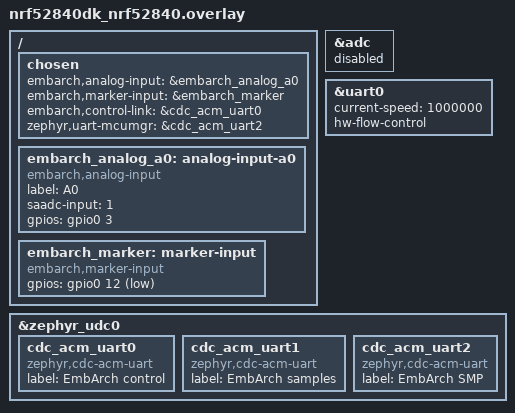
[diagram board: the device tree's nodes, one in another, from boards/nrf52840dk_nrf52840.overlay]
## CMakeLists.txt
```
# Shared application build (embarch-dev-bench/design.md §2) -- referenced,
# not copied, by every workspace under workspaces/*/app.

cmake_minimum_required(VERSION 3.20.0)

find_package(Zephyr REQUIRED HINTS $ENV{ZEPHYR_BASE})
project(embarch_dev_bench)

target_include_directories(app PRIVATE src)

target_sources(app PRIVATE
  src/main.c
  src/serial_protocol.c
  # EmbArch USB identity arithmetic (VID, PID, serial string); pure, so it
  # builds everywhere and a native_sim test pins it.
  src/usb_ids.c
  # embarch-study-designer/design.md §3 decisions 58-62: the `.eap` protocol
  # interpreter. Built for every board, including native_sim -- it is pure C
  # with no BLE and no Zephyr in it, which is what lets the ztest suite drive
  # the semantics directly (there is no real-vs-stub split to make here).
  src/eap_interp.c
  # embarch-dev-bench/design.md §3 decision 38: the Zephyr log backend that
  # forwards CONFIG_LOG output to Core as `LogLine`s. Built for every board,
  # including native_sim -- unlike ble_bridge there is no real-vs-stub
  # split here, since the file itself compiles to no-ops under CONFIG_LOG=n.
  src/dev_bench_log.c
  # decision 44: the advertiser census's Manufacturer Specific Data parsing and
  # rendering. Built for every board including native_sim, same reasoning as
  # eap_interp.c above -- it needs Zephyr's printk/util helpers but nothing
  # from the BT host, so a ztest can pin its offset arithmetic against a
  # synthetic payload on a board where ble_bridge_real.c itself never builds.
  src/scan_seen_mfg.c
  # dev-bench/007: the same failed-name census's bounded, no-partial-fragment
  # name-list append -- built for every board including native_sim, same
  # reasoning as scan_seen_mfg.c above, so a ztest can pin its truncation
  # behaviour even though ble_bridge_real.c itself never builds here.
  src/scan_seen_names.c
)

# The analog capture (dev-bench decisions 60 and 64): framing and sessions are
# pure and build everywhere, so a native_sim test drives them with a fake
# backend; only the backend and the USB port depend on the SoC.
target_sources(app PRIVATE
  src/analog_stream.c
  # Core's StudyStop, read while a study runs; pure, so a native_sim test drives it.
  src/study_stop.c
  src/analog_capture.c
)
if(CONFIG_SOC_SERIES_NRF52)
  # The one stated exception to portable-APIs-only (decision 60): nrfx SAADC.
  target_sources(app PRIVATE src/analog_source_nrf52.c)
else()
  target_sources(app PRIVATE src/analog_source_none.c)
endif()
target_sources_ifdef(CONFIG_USB_DEVICE_STACK_NEXT app PRIVATE src/samples_port.c)

# The native USB composite device, only where a board conf selects the "next"
# USB device stack (the nRF52840 DK).
target_sources_ifdef(CONFIG_USB_DEVICE_STACK_NEXT app PRIVATE src/usb_device.c)

# UICR REGOUT0 = 3.3 V at boot (nRF52840 DK on native USB), see the file.
target_sources_ifdef(CONFIG_EMBARCH_DEV_BENCH_REGOUT0_3V3 app PRIVATE src/board_regout0.c)

# embarch-dev-bench/design.md §3 decision 16: ble_bridge_real.c (real Zephyr BT
# host calls) vs ble_bridge_stub.c (canned Outcomes, no BLE host) are separate
# files, not #ifdef branches inside one -- CONFIG_ARCH_POSIX is true exactly
# for native_sim among this project's targets, so it's what picks between them.
if(CONFIG_ARCH_POSIX)
  target_sources(app PRIVATE src/ble_bridge_stub.c)
else()
  target_sources(app PRIVATE src/ble_bridge_real.c)
endif()

# embarch-dev-bench/design.md §3 decision 18: HelloAck.firmware_version.
# Best-effort `git describe`; falls back to a fixed placeholder outside a git
# checkout (e.g. a source tarball) or without git installed.
#
# Real bug found and fixed validating embarch-umbrella's stale-firmware
# doctor check (decision 25) against two real commits: `execute_process`
# only runs at CMake *configure* time, and CMake only reconfigures when one
# of its own tracked dependencies changes -- by default just CMakeLists.txt
# itself, not "the git commit checked out right now." An incremental
# `west build` after a plain `git commit` (no CMakeLists.txt edit) was
# silently re-linking with the *previous* configure's now-stale
# APP_FIRMWARE_VERSION baked in, for every translation unit, not just ones
# that happened to recompile -- exactly the false-negative decision 25's
# check exists to catch, self-inflicted by the build system itself. Fixed by
# making the checked-out commit itself a tracked configure dependency, so a
# commit (or branch switch) that changes it forces a reconfigure and a fresh
# `git describe`. Doesn't cover the plain-`--dirty` case (editing a tracked
# file without staging or committing touches neither of these) -- inherent
# to any git-describe-based scheme, not something CONFIGURE_DEPENDS can fix.
execute_process(
  COMMAND git rev-parse --git-dir
  WORKING_DIRECTORY ${CMAKE_CURRENT_SOURCE_DIR}
  OUTPUT_VARIABLE _embarch_git_dir
  OUTPUT_STRIP_TRAILING_WHITESPACE
  ERROR_QUIET
)
if(_embarch_git_dir)
  if(NOT IS_ABSOLUTE "${_embarch_git_dir}")
    set(_embarch_git_dir "${CMAKE_CURRENT_SOURCE_DIR}/${_embarch_git_dir}")
  endif()
  if(EXISTS "${_embarch_git_dir}/HEAD")
    set_property(DIRECTORY APPEND PROPERTY CMAKE_CONFIGURE_DEPENDS "${_embarch_git_dir}/HEAD")
    file(READ "${_embarch_git_dir}/HEAD" _embarch_head_contents)
    if(_embarch_head_contents MATCHES "^ref: (.*)$")
      string(STRIP "${CMAKE_MATCH_1}" _embarch_head_ref)
      set_property(DIRECTORY APPEND PROPERTY CMAKE_CONFIGURE_DEPENDS "${_embarch_git_dir}/${_embarch_head_ref}")
    endif()
  endif()
  if(EXISTS "${_embarch_git_dir}/index")
    set_property(DIRECTORY APPEND PROPERTY CMAKE_CONFIGURE_DEPENDS "${_embarch_git_dir}/index")
  endif()
endif()

execute_process(
  COMMAND git describe --always --dirty --abbrev=8
  WORKING_DIRECTORY ${CMAKE_CURRENT_SOURCE_DIR}
  OUTPUT_VARIABLE APP_FIRMWARE_VERSION
  OUTPUT_STRIP_TRAILING_WHITESPACE
  ERROR_QUIET
)
if(NOT APP_FIRMWARE_VERSION)
  set(APP_FIRMWARE_VERSION "unknown")
endif()
target_compile_definitions(app PRIVATE APP_FIRMWARE_VERSION="${APP_FIRMWARE_VERSION}")

# Where embarch-study-designer lives. No target links the crate; every target
# reads its wire schema version and its limits and wire enums out of the
# crate's source at configure time, because hand-mirroring them is how the
# schema number went stale twice (see below).
if(DEFINED ENV{EMBARCH_STUDY_DESIGNER_PATH})
  set(ESSD_DIR "$ENV{EMBARCH_STUDY_DESIGNER_PATH}")
else()
  # CMAKE_CURRENT_SOURCE_DIR here is workspaces/<name>/app, itself a
  # symlink to the real app/ (§2's tree). Resolve *that* symlink first, in
  # its own get_filename_component call -- CMake's REALPATH collapses ".."
  # textually before resolving symlinks, so appending "../../embarch-study-
  # designer" and resolving in one call never actually follows the
  # symlink: the ".." components cancel the still-unresolved "app" segment
  # lexically, landing in workspaces/embarch-study-designer (which doesn't
  # exist) instead of climbing out of the real app/'s real parent. Found
  # standing up workspaces/espressif (embarch-dev-bench/design.md's
  # ESP32-C5 interim decision) -- a real CMake-path-resolution bug, latent
  # in every other workspace too, just unnoticed because plain ABSOLUTE
  # (the original code here) happened to still be wrong in the same way
  # nobody hit until a workspace where the surrounding symlink chain
  # differed enough to surface it.
  get_filename_component(ESSD_APP_REALDIR "${CMAKE_CURRENT_SOURCE_DIR}" REALPATH)
  get_filename_component(ESSD_DIR "${ESSD_APP_REALDIR}/../../embarch-study-designer" ABSOLUTE)
endif()
if(NOT EXISTS "${ESSD_DIR}/Cargo.toml")
  message(FATAL_ERROR "embarch-dev-bench: embarch-study-designer not found at ${ESSD_DIR} -- set EMBARCH_STUDY_DESIGNER_PATH if it isn't a sibling of this repo.")
endif()

# Every crate limit and `.eap` wire enum the headers size or decode by,
# derived from the crate rather than typed (decision 56).
include(${CMAKE_CURRENT_SOURCE_DIR}/cmake/crate_limits.cmake)

# The wire schema version `HelloAck` reports (decision 20), read out of the
# crate rather than mirrored by hand in C, for every target.
#
# It was a hand-written `#define`, and it went stale twice: found four bumps
# behind at v4 while implementing v9, fixed to 9, and found stale again at 9
# one bump later when decision 47 took the wire to 10. The comment written the
# first time already said nothing compares this number against the crate --
# which was true, and stayed true, and let the same defect recur immediately.
# Reading it from the crate's own source is what actually closes that, and the
# CONFIGURE_DEPENDS below is what makes an edit to that file re-run this
# instead of leaving a stale value baked in -- the same trap APP_FIRMWARE_VERSION
# hit above. Real boards used to get the number by cross-compiling the crate
# into a staticlib and calling into it (decision 8); that was the only live call
# into the staticlib, so the staticlib is gone and every board reads it here.
set(ESSD_SCHEMA_SRC "${ESSD_DIR}/src/schema_version.rs")
if(NOT EXISTS "${ESSD_SCHEMA_SRC}")
  message(FATAL_ERROR "embarch-dev-bench: ${ESSD_SCHEMA_SRC} not found -- the build reads DEV_BENCH_WIRE_SCHEMA_VERSION from it.")
endif()
set_property(DIRECTORY APPEND PROPERTY CMAKE_CONFIGURE_DEPENDS "${ESSD_SCHEMA_SRC}")
file(READ "${ESSD_SCHEMA_SRC}" _essd_schema_src)
if(NOT _essd_schema_src MATCHES "pub const DEV_BENCH_WIRE_SCHEMA_VERSION: u32 = ([0-9]+)")
  message(FATAL_ERROR "embarch-dev-bench: could not read DEV_BENCH_WIRE_SCHEMA_VERSION out of ${ESSD_SCHEMA_SRC}.")
endif()
target_compile_definitions(app PRIVATE DEV_BENCH_WIRE_SCHEMA_VERSION=${CMAKE_MATCH_1}u)
message(STATUS "embarch-dev-bench: dev-bench wire schema version ${CMAKE_MATCH_1} (from the crate)")
```

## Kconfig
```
# Application Kconfig, sourced automatically by Zephyr for the app directory.
# Shared by every workspace under workspaces/* (each one's app/ is a symlink to
# this directory, embarch-dev-bench/design.md §2).
#
# **An app Kconfig replaces Zephyr's own root, it does not extend it**, so it
# has to `source "Kconfig.zephyr"` itself or every Zephyr symbol vanishes and
# the build aborts on the resulting warnings. Found the hard way adding the
# first symbol here.

mainmenu "embarch-dev-bench"

config EMBARCH_DEV_BENCH_PANIC_AT_HANDSHAKE
	bool "Deliberately k_panic() right after the handshake diagnostic"
	help
	  A debug-only build that crashes on purpose, to exercise decision 38's
	  fatal-error path — the one part of it that has never run (§4).
	  log_panic() switching to synchronous, lock-free writing is what should
	  carry a Zephyr crash dump to Core as LogLines, and nothing has
	  deliberately crashed this firmware since it was written.

	  The question it answers is specific: dev-bench resets mid-study while
	  transmitting a long StepResult, and no crash dump ever arrives. That is
	  either because the reset is not a Zephyr panic, or because this path
	  does not deliver. A build that panics on command distinguishes them —
	  a dump in dev-bench.log means the path works and the real reset is
	  something else (brownout and a watchdog lead the alternatives); no dump
	  means the path itself is broken and the absence of one during a real
	  reset says nothing.

	  Never enable this in a build meant to run a study: it panics at every
	  handshake, so no study can start.
	default n

config EMBARCH_DEV_BENCH_REGOUT0_3V3
	bool "Set UICR REGOUT0 to 3.3 V at boot when unset"
	depends on SOC_NRF52840
	help
	  For an nRF52840 DK powered only from its native USB: the chip runs in
	  high-voltage mode and its VDD comes from regulator stage 0, whose
	  erased default is 1.8 V. With this on, board_regout0.c writes 3.3 V to
	  UICR REGOUT0 the first time it boots with the default, then resets
	  once, so an external analog front end gets 3.3 V on VDD.

config EMBARCH_ANALOG_MAX_CHANNELS
	int "Most analog channels one session can carry"
	range 1 8
	default 1
	help
	  Sizes every sample block buffer. The block format carries any channel
	  count; the only backend (nRF52 SAADC on its internal timer) samples
	  one channel, so a larger value only reserves RAM until a multi-channel
	  backend exists.

config EMBARCH_ANALOG_STREAM_SLOTS
	int "Sample blocks buffered between the ADC and the samples port"
	range 2 32
	default 8
	help
	  Each slot is one block (528 bytes for one channel, 8 ms at 32 ksps).
	  When all are in use the next block is dropped and counted, never
	  waited for.

config EMBARCH_SAMPLES_PORT_RING_BLOCKS
	int "Sample blocks the samples USB port can queue"
	depends on USB_DEVICE_STACK_NEXT
	range 2 32
	default 8
	help
	  The transmit ring in front of the samples CDC ACM port. A block that
	  does not fit whole is refused and counted lost.

source "Kconfig.zephyr"
```

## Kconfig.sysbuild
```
# Sysbuild Kconfig for this app. Replaces the sysbuild root, so it sources
# Zephyr's own first.
#
# MCUboot is built for the nRF52840 DK only (image updates over the SMP USB
# port). Every other board keeps its current flash layout: a default on the
# bootloader choice, set before Zephyr's own declaration so it is the first
# default found.
choice BOOTLOADER
	default BOOTLOADER_MCUBOOT if BOARD = "nrf52840dk"
endchoice

source "share/sysbuild/Kconfig"
```

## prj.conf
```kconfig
# Shared baseline Kconfig, both workspaces (embarch-dev-bench/design.md §2).

# embarch-dev-bench/design.md §3 decision 7: dev-bench's own log output
# travels as a `LogLine` DevBenchMessage, not raw text -- so nothing else
# (the boot banner, a log backend, the shell) may also write to the link UART
# (the board's `zephyr,console` chosen device, see main.c), or it would corrupt
# COBS framing on the shared wire. No on-board status indication for v1 either
# way (§1) -- this firmware's state is observable only through
# embarch-core/study_status, not local console output.
#
# CONFIG_CONSOLE itself is left alone (native_sim's board Kconfig
# unconditionally force-selects console support and errors out if this tries
# to turn it off) -- disabling the things that actually call printk/log on it
# is enough, since nothing else writes to this UART unprompted.
CONFIG_BOOT_BANNER=n

# --- logging subsystem (design.md §3 decision 38) ------------------------
#
# CONFIG_LOG was `n` here from decision 7 until decision 38, and that had a
# real cost: every LOG_* call in this app and in every Zephyr subsystem it uses
# (BT host, drivers) compiled to nothing, and so did the fatal-error dump, so a
# bench that rebooted or faulted mid-study was *completely silent* from Core's
# side (see main.c's handle_hello for the study that made that concrete). What
# decision 7 actually forbids is raw log text on the shared wire -- not the
# logging subsystem itself. dev_bench_log.c is a log backend that formats each
# record and hands it to a `LogLine`, i.e. exactly the channel decision 7
# specified, so the subsystem can be on without a byte of unframed text ever
# reaching the UART.
CONFIG_LOG=y
CONFIG_LOG_OUTPUT=y

# Deferred, never immediate, and this is load-bearing rather than a default
# worth restating: in immediate mode a backend runs in the caller's context,
# including ISRs and the BT RX thread, and dev_bench_log.c's sink takes
# main.c's `link_tx_mutex` and blocks on uart_poll_out -- illegal from an ISR
# and a latency spike everywhere else. Deferred mode moves every backend call
# onto the log processing thread, which is what makes one link writer more
# (alongside the dispatch loop and the transcript TX thread) safe.
CONFIG_LOG_MODE_DEFERRED=y
CONFIG_LOG_PROCESS_THREAD=y
# log_output formatting plus dbm_encode_frame's call depth on top of it. The
# 1 KB default is Zephyr's sizing for a UART backend that does neither.
CONFIG_LOG_PROCESS_THREAD_STACK_SIZE=2048

# The two backends Zephyr would otherwise enable *by default* on these boards,
# both of which would break something here:
#   - LOG_BACKEND_UART defaults to y whenever there is a UART console, and
#     that console IS this link -- it would write raw text straight onto the
#     COBS wire, the precise failure decision 7 exists to prevent. This line
#     is the single most important one in this block.
#   - LOG_BACKEND_RTT defaults to y on a SEGGER-probed board (the nRF54L15DK).
#     Harmless to the wire, but it costs RAM on boards whose SRAM has already
#     overflowed twice at link time (§3 decision 27, and main.c's tx_scratch
#     consolidation), for a second channel nothing in this suite reads.
CONFIG_LOG_BACKEND_UART=n
CONFIG_LOG_BACKEND_RTT=n

# A *protection*, not a convenience: with this on, any stray printk (Zephyr
# internals, a future line in this app) is routed through the logging
# subsystem and comes out as a framed `LogLine` instead of raw bytes on the
# protocol wire. Without it, one printk anywhere corrupts a frame -- which is
# why the ESP32-C5 overlay's own comment had to record "no stray printk on
# this path -- checked, not assumed" as a prerequisite for reading a decode
# failure. This makes that check unnecessary rather than merely passed.
CONFIG_LOG_PRINTK=y

# --- per-study verbosity (design.md §3 decision 39) ----------------------
#
# Decision 38 shipped CONFIG_LOG_DEFAULT_LEVEL=2, i.e. it kept the link quiet
# by *compiling out* everything above warn. That was the right instinct about
# bandwidth -- a 128-byte LogLine frame is ~1.3 ms of a 1 Mbaud wire the study
# protocol is also using -- and the wrong mechanism: it made the choice once,
# for every study, at whatever level whoever last edited this file picked. A
# BLE-heavy study that needed the BT host's own account of a failure could only
# get it by editing this line, rebuilding, and reflashing the bench.
#
# So: compile everything in, and filter at runtime per study instead. A
# `Study` carries `dev_bench_log_level` (embarch-study-designer's
# DevBenchLogLevel, schema v13), main.c applies it for the study's duration and
# reverts to DEV_BENCH_LOG_BOOT_LEVEL (warn) afterwards, so an idle bench is
# exactly as quiet as it was before this change.
#
# The cost of compiling in DBG is flash, not SRAM -- log format strings live in
# rodata, which on both supported boards is flash-mapped (the ESP32-C5's
# drom0_0_seg was at 0.55% of 8 MB). CONFIG_LOG_RUNTIME_FILTERING's own cost
# *is* SRAM (one filter word per log source), which is why the number below was
# measured against a real build rather than assumed.
CONFIG_LOG_DEFAULT_LEVEL=4
CONFIG_LOG_RUNTIME_FILTERING=y

# embarch-dev-bench/design.md §3 decision 21: `struct dev_bench_message`'s
# union now includes `struct dbm_study_start`, which embeds a full
# DBM_MAX_STEPS_PER_STUDY-sized `struct dbm_step` array (StudyStart's own
# wire worst case, see serial_protocol.h) -- several KB per message value.
# main.c keeps its own message buffers `static` rather than stack locals for
# exactly this reason, but Zephyr's small default main-thread stack (1024
# bytes) isn't enough headroom for the rest of main()'s own call depth
# (ble_bridge_execute, uart_poll_*, etc.) alongside that; bumped well past
# what's actually needed as margin, since both boards have ample RAM for one
# always-alive thread stack.
CONFIG_MAIN_STACK_SIZE=8192

# embarch-dev-bench/design.md §3 decision 29: the link's inbound path must be
# interrupt-driven, not polled. main.c's dispatch loop used to call
# uart_poll_in directly and sleep 1ms whenever the FIFO was momentarily
# empty; at this link's 1 Mbaud that is ~100 bytes of arrivals per sleep,
# against a 128-byte hardware FIFO, so every frame larger than the FIFO lost
# bytes and failed to decode -- presenting as "no message received from
# dev-bench", never as an error. An ISR now drains the FIFO into a ring
# buffer (see main.c's `link_rx_ring`) so frame parsing can never be what the
# FIFO is waiting on.
CONFIG_UART_INTERRUPT_DRIVEN=y
CONFIG_RING_BUFFER=y

# embarch-study-designer/design.md §3 decision 47, embarch-core/design.md §3
# decision 35: `HelloAck` reports this board's own factory-unique chip ID, so
# Core can confirm the board answering on the serial link is the same silicon
# its JTAG probe just verified -- the two are physically separate USB devices
# since the port migration, and nothing observable over USB tied them
# together before this.
#
# main.c's read_hardware_id() is guarded on CONFIG_HWINFO and reports an empty
# string without it, so a board target whose SoC has no hwinfo driver still
# builds and still handshakes -- it just cannot answer the question. native_sim
# is exactly that case.
CONFIG_HWINFO=y

# CRC-32/ISO-HDLC of the analog stream's start header and blocks
# (src/analog_stream.c), for every board that builds it.
CONFIG_CRC=y
```

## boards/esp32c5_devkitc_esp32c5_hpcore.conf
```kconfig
# ESP32-C5-WROOM-1-specific Kconfig, auto-merged by Zephyr's build system for
# board target esp32c5_devkitc/esp32c5/hpcore (filename matches the full
# target with slashes replaced by underscores, same convention as
# nrf54l15dk_nrf54l15_cpuapp.conf).
#
# embarch-dev-bench/design.md §3 decision [interim ESP32-C5]: temporary
# substitute dev-bench board while the real nRF54L15DK replacement is in
# transit (broken unit RMA'd, ETA ~1 week from 2026-08-19). Values below were
# *not* blindly copied from the Nordic file -- each was checked empirically
# against a real `west build` for this board; see that decision's own text
# for what differed and why.
CONFIG_BT=y
CONFIG_BT_PERIPHERAL=y
CONFIG_BT_CENTRAL=y
CONFIG_BT_SMP=y
CONFIG_BT_DEVICE_NAME="embarch-dev-bench"

# BT_ESP32 (drivers/bluetooth/hci/Kconfig.esp32) is the HCI driver for
# Espressif's own BLE controller blob (libble_app.a etc., fetched via
# `west blobs fetch hal_espressif`) -- it is *not* directly settable here
# (empirically: "is assigned in a configuration file, but is not directly
# user-configurable (has no prompt)" -- it has no `prompt` in its Kconfig
# entry). It gets selected automatically once CONFIG_BT is on for a board
# whose SoC provides it, so no line for it belongs in this file at all.

# Unlike the nRF54L15DK (SoftDevice Controller, BT_MAX_CONN=2 needed because
# central/peripheral slots are carved out of one pool), Espressif's ESP32
# controller budgets central and peripheral connections independently
# (ESP32_BT_CTLR_LE_MAX_CONN, default 3) -- BT_MAX_CONN=2 here is just "one
# central + one peripheral link," not a controller-slot workaround.
CONFIG_BT_MAX_CONN=2

CONFIG_BT_GATT_CLIENT=y
CONFIG_BT_GATT_AUTO_DISCOVER_CCC=y

# Same reasoning as the nRF54L15DK conf: every BLE action runs synchronously
# on the main thread, blocking on semaphores across discovery/read/write and
# building advertising data on its stack.
#
# Real bug found and fixed, Milestone 3 (Study Designer: Feature-Branch
# Iteration): this line used to read 2048, silently overriding the shared
# app/prj.conf's own CONFIG_MAIN_STACK_SIZE=8192 -- Zephyr's board-conf
# fragment is merged *after* prj.conf, so the later value wins with no
# warning either build ever surfaced. Confirmed empirically against a real
# build's resolved build/zephyr/.config (2048, not 8192) before this fix.
# Harmless while dispatch_study only ever ran Action::BleAdvertise (a
# shallow call chain), but real Action::GattDiscover/GattMonitorAll dispatch
# (embarch-study-designer/design.md §3 decisions 31/32) is the first time
# this main thread's call depth actually reaches into BLE central-role GATT
# discovery/subscribe code -- restoring prj.conf's already-vetted margin here
# rather than leaving a real hardware build silently running a quarter of it.
CONFIG_MAIN_STACK_SIZE=8192

# Deliberately not setting CONFIG_BT_SETTINGS -- same RAM-only bonding-table
# posture as the nRF54L15DK conf (decision 11), unaffected by which board is
# running the firmware.

# --- GATT transcript (embarch-dev-bench/design.md §3 decision 36) ---
#
# ble_bridge_real.c's transcript_emit() builds one `struct
# ble_transcript_entry` (~290 bytes) as a stack local, deliberately rather
# than in a shared static: it is called from both the BT RX thread (anything
# inbound) and whichever thread called ble_bridge_execute, and a shared
# staging buffer would tear under a notification arriving mid-emit. Zephyr's
# default BT RX stack has no room for that frame on top of the GATT
# discovery/subscribe call depth already running there, so it is raised here
# rather than left to fail as an intermittent stack overflow under exactly
# the notification bursts this feature exists to capture.
CONFIG_BT_RX_STACK_SIZE=3072

# One ATT MTU's worth of notification is what DBM_MAX_TRANSCRIPT_PAYLOAD_LEN
# (serial_protocol.h) is sized for. Zephyr's defaults (L2CAP TX MTU 65) would
# cap a single notification at 62 bytes, silently fragmenting anything longer
# -- a shell/NUS response most of all -- into rows that each look like a
# separate event. 247 is the usual practical ceiling for one LL PDU with data
# length extension, and 244 = 247 - 3 bytes of ATT header.
CONFIG_BT_L2CAP_TX_MTU=247
CONFIG_BT_BUF_ACL_RX_SIZE=251
CONFIG_BT_BUF_ACL_TX_SIZE=251
```

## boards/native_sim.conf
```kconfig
# native_sim-specific Kconfig (embarch-dev-bench/design.md §3 decision 16).
# ble_bridge_stub.c pulls in no Zephyr BT Kconfig at all.
#
# native_sim's `zephyr,console` chosen node (uart0, "zephyr,native-pty-uart")
# only gets a real uart_poll_in/uart_poll_out-capable driver instance when
# CONFIG_SERIAL is on -- without it, the board falls back to a raw POSIX
# console with no standard UART device at all, which main.c's DEVICE_DT_GET
# needs. This is Zephyr's own native UART peripheral emulation (backed by a
# host PTY under the hood), not a bespoke test transport of our own --
# decision 16's "no virtual-PTY serial transport" is about not building extra
# test-only plumbing on top of this, not about avoiding native_sim's normal
# UART support.
CONFIG_SERIAL=y
CONFIG_UART_NATIVE_PTY=y

# --- logging (embarch-dev-bench/design.md §3 decision 38) ----------------
#
# Deliberately NOT turning off CONFIG_LOG_BACKEND_NATIVE_POSIX, unlike the
# UART and RTT backends the shared prj.conf disables. That backend writes to
# the host process's *stdout*, and this board's link is a separate PTY
# (CONFIG_UART_NATIVE_PTY above), so it cannot corrupt COBS framing the way
# LOG_BACKEND_UART would on a real board -- and having log records visible in
# the terminal that launched zephyr.exe is exactly what a host-side sanity
# board is for. Confirmed by reading the resolved build/zephyr/.config, not
# assumed: NATIVE_POSIX is the only other backend this board enables.
```

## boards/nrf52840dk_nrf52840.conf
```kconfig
# nRF52840DK-specific Kconfig, auto-merged by Zephyr for board target
# nrf52840dk/nrf52840 (same filename convention as the nRF54L15DK fragment).
#
# Same feature set as the nRF54L15DK image: the BLE central/peripheral bridge
# on the SoftDevice Controller, with the comments on each symbol kept in
# nrf54l15dk_nrf54l15_cpuapp.conf rather than copied here.
CONFIG_BT=y
CONFIG_BT_PERIPHERAL=y
CONFIG_BT_CENTRAL=y
CONFIG_BT_SMP=y
CONFIG_BT_DEVICE_NAME="embarch-dev-bench"
CONFIG_BT_MAX_CONN=2
CONFIG_BT_GATT_CLIENT=y
CONFIG_BT_GATT_AUTO_DISCOVER_CCC=y
CONFIG_MAIN_STACK_SIZE=8192
CONFIG_BT_RX_STACK_SIZE=3072
CONFIG_BT_L2CAP_TX_MTU=247
CONFIG_BT_BUF_ACL_RX_SIZE=251
CONFIG_BT_BUF_ACL_TX_SIZE=251

# REGOUT0 = 3.3 V at boot when the DK runs from its native USB (src/board_regout0.c).
CONFIG_EMBARCH_DEV_BENCH_REGOUT0_3V3=y

# --- native USB: composite device, three CDC ACM ports (src/usb_device.c) ---
# The "next" USB device stack of the pinned NCS (v3.4.0, Zephyr 4.4 base).
CONFIG_USB_DEVICE_STACK_NEXT=y
CONFIG_USBD_CDC_ACM_CLASS=y
# The nRF52840's unique ID is 8 bytes; the serial string is that ID in hex.
CONFIG_USBD_HWINFO_DEVID_LENGTH=8

# --- SMP on the third port: image updates through MCUboot ---
# Serial (console-framed) transport, the framing embarch-smp speaks.
CONFIG_MCUMGR=y
CONFIG_MCUMGR_TRANSPORT_UART=y
CONFIG_MCUMGR_GRP_OS=y
CONFIG_MCUMGR_GRP_IMG=y
CONFIG_MCUBOOT_BOOTUTIL_LIB=y
CONFIG_IMG_MANAGER=y
CONFIG_STREAM_FLASH=y
CONFIG_FLASH=y
CONFIG_FLASH_MAP=y
CONFIG_BASE64=y
CONFIG_UART_MCUMGR=y
CONFIG_NET_BUF=y
CONFIG_ZCBOR=y

# --- analog capture (src/analog_source_nrf52.c) ---
# The SAADC through nrfx directly; the overlay disables &adc, so Zephyr's ADC
# driver does not also claim it. Pins come from the overlay's chosen nodes.
CONFIG_NRFX_SAADC=y
CONFIG_GPIO=y

# The MPU driver's own debug lines are compiled out on this board. A Cortex-M4
# guards each thread's stack with an MPU region reprogrammed on every context
# switch, and arm_mpu.c logs each reprogramming at DBG: with the app's
# compiled-in DBG ceiling (prj.conf, decision 39) every sleep made a deferred
# log message mid-switch, so log_flush() in dev_bench_log_set_level() always
# found an uncommitted message at the head of the buffer and main() never ran
# (2026-11-25). The nRF54L15DK's Cortex-M33 uses its stack-limit register and
# never reprograms the MPU on a switch.
CONFIG_MPU_LOG_LEVEL_INF=y
```

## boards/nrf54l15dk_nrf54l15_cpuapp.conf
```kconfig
# nRF54L15DK-specific Kconfig, auto-merged by Zephyr's build system for board
# target nrf54l15dk/nrf54l15/cpuapp (filename matches the full target with
# slashes replaced by underscores -- Zephyr's standard board-conf-fragment
# convention, no extra CMake wiring needed).
#
# embarch-dev-bench/design.md §3 decisions 3/5/11: SoftDevice Controller,
# Just Works pairing, bonds RAM-only (achieved simply by never enabling
# CONFIG_BT_SETTINGS below -- Zephyr's default without it is RAM-only).
CONFIG_BT=y
CONFIG_BT_PERIPHERAL=y
CONFIG_BT_CENTRAL=y
CONFIG_BT_SMP=y
CONFIG_BT_DEVICE_NAME="embarch-dev-bench"

# Two link slots, not one -- and NOT a relaxation of design decision 15's
# one-DUT-at-a-time rule. With the SoftDevice Controller, the central role gets
# `BT_MAX_CONN - BT_CTLR_SDC_PERIPHERAL_COUNT` slots (nrf/subsys/bluetooth/
# controller/Kconfig), and PERIPHERAL_COUNT defaults to 1 whenever
# BT_PERIPHERAL is on -- so BT_MAX_CONN=1 would leave the central role zero
# slots and break every central-role BleConnect, while still building cleanly.
# Two is also NCS's own default for this exact combination. The
# one-connection-at-a-time invariant is enforced in ble_bridge_real.c's
# execute_connect (it refuses to open a second link), not by this budget.
CONFIG_BT_MAX_CONN=2

# ble_bridge_real.c's DataExchange path acts as a GATT *client* against the DUT:
# service/characteristic discovery, read, write-with-response, and
# notify/indicate subscriptions. BT_CENTRAL alone doesn't bring the client role
# in.
CONFIG_BT_GATT_CLIENT=y
# Lets bt_gatt_subscribe() find a characteristic's CCC descriptor itself
# (subscribe_params.ccc_handle = BT_GATT_AUTO_DISCOVER_CCC_HANDLE), so
# ble_bridge_real.c doesn't need a third hand-rolled discovery pass. The
# subscribe_params fields it uses for that (end_handle/disc_params) only exist
# when this is enabled -- turning it off is a compile error there, not a
# silent behavior change.
CONFIG_BT_GATT_AUTO_DISCOVER_CCC=y

# Every BLE action runs synchronously on the main thread, which now waits on
# semaphores across discovery/read/write instead of returning immediately, and
# builds advertising data on its stack. 2 KiB leaves headroom over the nRF
# default (1 KiB) for that.
#
# Real bug found and fixed, Milestone 3 (Study Designer: Feature-Branch
# Iteration): this line used to silently override the shared app/prj.conf's
# own CONFIG_MAIN_STACK_SIZE=8192, since Zephyr merges a board-conf fragment
# *after* prj.conf and the later value wins with no warning -- confirmed
# empirically via the espressif board's own resolved .config before this fix
# (the identical bug, same root cause, present in this file too). Restoring
# prj.conf's already-vetted margin here now that real GATT-discovery dispatch
# (embarch-study-designer/design.md §3 decisions 31/32) is the first thing to
# actually exercise this main thread's deeper BLE-central call chains.
CONFIG_MAIN_STACK_SIZE=8192

# NOT setting CONFIG_BT_SETTINGS (and therefore not CONFIG_SETTINGS/CONFIG_FLASH
# either) is what keeps the BT bonding table RAM-only, per decision 11 --
# there is deliberately no flash-backed persistence to opt into here.

# --- GATT transcript (embarch-dev-bench/design.md §3 decision 36) ---
#
# ble_bridge_real.c's transcript_emit() builds one `struct
# ble_transcript_entry` (~290 bytes) as a stack local, deliberately rather
# than in a shared static: it is called from both the BT RX thread (anything
# inbound) and whichever thread called ble_bridge_execute, and a shared
# staging buffer would tear under a notification arriving mid-emit. Zephyr's
# default BT RX stack has no room for that frame on top of the GATT
# discovery/subscribe call depth already running there, so it is raised here
# rather than left to fail as an intermittent stack overflow under exactly
# the notification bursts this feature exists to capture.
CONFIG_BT_RX_STACK_SIZE=3072

# One ATT MTU's worth of notification is what DBM_MAX_TRANSCRIPT_PAYLOAD_LEN
# (serial_protocol.h) is sized for. Zephyr's defaults (L2CAP TX MTU 65) would
# cap a single notification at 62 bytes, silently fragmenting anything longer
# -- a shell/NUS response most of all -- into rows that each look like a
# separate event. 247 is the usual practical ceiling for one LL PDU with data
# length extension, and 244 = 247 - 3 bytes of ATT header.
CONFIG_BT_L2CAP_TX_MTU=247
CONFIG_BT_BUF_ACL_RX_SIZE=251
CONFIG_BT_BUF_ACL_TX_SIZE=251
```

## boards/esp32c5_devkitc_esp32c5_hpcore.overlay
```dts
/*
 * ESP32-C5-WROOM-1 interim dev-bench board (embarch-dev-bench/design.md's
 * ESP JTAG interim decision). Auto-merged by Zephyr's board devicetree
 * overlay convention (flat filename matching the board target, same as this
 * board's own .conf fragment) -- no extra CMake wiring needed.
 *
 * Second real end-to-end finding on this exact link, Milestone 3 (Study
 * Designer: Feature-Branch Iteration), 2026-08-20 -- this file previously
 * repointed the console/protocol link at `usb_serial` (the native USB
 * JTAG/serial peripheral, same physical USB-C port used for JTAG flashing),
 * because `uart0`'s header pins were believed disconnected from anything
 * the host could reach. That's wrong for this specific board: the
 * ESP32-C5-DevKitC-1 has a *second* USB-C port, wired to `uart0` through its
 * own onboard USB-UART bridge chip, entirely separate from the native USB
 * JTAG/serial port both live in the same DTS as `zephyr,console = &uart0`
 * (the board's own upstream default) already assumed. Found live: the first
 * real `run_study` against `usb_serial` got past Core's dev-bench port
 * *detection* (unambiguous once `EMBARCH_DEV_BENCH_SERIAL` was set) but
 * failed decoding `HelloAck` -- consistent with the native USB JTAG/serial
 * peripheral's poll-mode driver not reliably carrying this link's 1 Mbaud
 * binary protocol, not a framing/logic bug (`CONFIG_LOG=n`, no stray
 * `printk` on this path -- checked, not assumed). Switching back to the
 * board's own default console (`uart0`, over its dedicated UART USB-C port)
 * tests that theory with zero rewiring: both USB-C ports stay connected,
 * JTAG flashing/reset keep using the native one, the protocol link moves to
 * the UART one. `current-speed` overridden to 1 Mbaud here (the upstream
 * default of 115200 predates this link needing to match
 * `embarch-core::dev_bench_link::DEV_BENCH_BAUD`). `usb_serial` is left
 * enabled -- harmless if unused, and JTAG/flashing over that same physical
 * port is unaffected by what Zephyr's console is chosen to.
 */

&uart0 {
	current-speed = <1000000>;
};
```

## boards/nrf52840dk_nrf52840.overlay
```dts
/*
 * nRF52840DK dev-bench board. Auto-merged by Zephyr's board devicetree
 * overlay convention, like the nRF54L15DK's overlay.
 *
 * The control link is the native USB "EmbArch control" CDC ACM port, named by
 * the `embarch,control-link` chosen entry below (decision 62); the link
 * protocol on it is unchanged. The J-Link UART (`zephyr,console` is `&uart0`,
 * VCOM0 of the on-board J-Link) is no longer the link, but keeps its 1 Mbaud
 * and flow-control settings so a build that drops the chosen entry falls back
 * to the same link the nRF54L15DK uses. `uart0_default` carries RTS on P0.05 and CTS on P0.07 alongside TX P0.06 /
 * RX P0.08, so nothing is rewired.
 *
 * Analog source. The input is a devicetree node the analog-source code reads
 * (`DT_CHOSEN(embarch_analog_input)`), never a pin number in C. It is the
 * Arduino-header A0 pin, P0.03 = AIN1 (the DK's own `arduino_adc` map says
 * the same). The marker input is the DK's BUTTON2 (P0.12); BUTTON1 stays free
 * for the MCUboot recovery button (`mcuboot-button0`).
 *
 * The SAADC is taken by the analog source through nrfx directly (advanced
 * mode with its internal timer, which Zephyr's ADC driver does not expose),
 * so `&adc` is disabled here: Zephyr's ADC driver must not also claim it. The
 * DK's `arduino_adc` connector node keeps referring to it as a plain phandle,
 * which needs no driver.
 */

/ {
	chosen {
		embarch,analog-input = &embarch_analog_a0;
		embarch,marker-input = &embarch_marker;
		embarch,control-link = &cdc_acm_uart0;
	};

	embarch_analog_a0: analog-input-a0 {
		compatible = "embarch,analog-input";
		label = "A0";
		saadc-input = <1>;	/* P0.03 = AIN1 */
		gpios = <&gpio0 3 0>;
	};

	embarch_marker: marker-input {
		compatible = "embarch,marker-input";
		/* BUTTON2 (P0.12), to ground, so active low with the pull-up. */
		gpios = <&gpio0 12 (GPIO_PULL_UP | GPIO_ACTIVE_LOW)>;
	};
};

&adc {
	status = "disabled";
};

&uart0 {
	current-speed = <1000000>;
	hw-flow-control;
};

/*
 * Native USB: three CDC ACM ports on the nRF USB connector (src/usb_device.c).
 * The `label` of each is the port's USB interface string; the order is the
 * port order (cdc_acm_0, cdc_acm_1, cdc_acm_2 in the class registry).
 * The SMP port is the MCUmgr transport: image updates through MCUboot.
 * The control port is the Core link (`embarch,control-link`); the samples
 * port carries the analog stream (src/samples_port.c).
 */
&zephyr_udc0 {
	cdc_acm_uart0: cdc_acm_uart0 {
		compatible = "zephyr,cdc-acm-uart";
		label = "EmbArch control";
	};

	cdc_acm_uart1: cdc_acm_uart1 {
		compatible = "zephyr,cdc-acm-uart";
		label = "EmbArch samples";
	};

	cdc_acm_uart2: cdc_acm_uart2 {
		compatible = "zephyr,cdc-acm-uart";
		label = "EmbArch SMP";
	};
};

/ {
	chosen {
		/* The board file points this at the J-Link UART, which is the
		 * console and the control link. */
		zephyr,uart-mcumgr = &cdc_acm_uart2;
	};
};
```

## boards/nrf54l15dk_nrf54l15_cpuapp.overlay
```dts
/*
 * nRF54L15DK dev-bench board (embarch-dev-bench/design.md §3 decision 26's
 * successor -- this board is the dev bench again as of 2026-08-31). Auto-
 * merged by Zephyr's board devicetree overlay convention (flat filename
 * matching the board target, same as this board's own .conf fragment and as
 * the ESP32-C5's overlay) -- no extra CMake wiring needed.
 *
 * The only thing this file has to say is the baud rate. `zephyr,console` on
 * this board is already `&uart20` (nrf54l_05_10_15_cpuapp_common.dtsi's own
 * chosen block), wired through the DK's onboard J-Link OB to VCOM1, USB
 * interface 2 (decision 43: enrol it with `link_port_interface = 2`) -- so
 * unlike the ESP32-C5, which had to be moved off its native USB-Serial/JTAG
 * peripheral onto a separate bridge chip, nothing here needs repointing.
 * What does need overriding is `current-speed`: the board's upstream default
 * is 115200, and this link must match `embarch-core::dev_bench_link::
 * DEV_BENCH_BAUD` (1 Mbaud) exactly or Core's very first `Hello` fails to
 * decode.
 *
 * uart30 is left at its own 115200 default and unused, and it is
 * deliberately NOT given a role here:
 * app/prj.conf's decision-7 block turns off every log backend that would
 * write raw text, so there is nothing left that wants a second console, and
 * a second enabled UART would only add a candidate for
 * `embarch-topology`'s port detection to have to disambiguate.
 */

&uart20 {
	current-speed = <1000000>;
	/* **Hardware flow control, because this link silently loses bytes
	 * without it.** At 1 Mbaud the host driver's default ~4 KB receive
	 * buffer holds about 40 ms of traffic, so any stall longer than that on
	 * Core's side drops a contiguous run of bytes mid-frame. COBS resyncs at
	 * the next delimiter and the frame is simply gone; ordinary
	 * DevBenchMessages carry no CRC (only `Study` does), so nothing detects
	 * it except a decode failure. A 10 h PPG drain lost three
	 * `StreamChunkBatch` frames that way -- 976 bytes, four 244-byte
	 * notifications, 3 of 598 records damaged -- and the capture was
	 * reported `truncated: false`.
	 *
	 * Core reading on its own thread (embarch-core's `dev_bench_link`)
	 * removes the stall this firmware was paying for; CTS is what makes the
	 * loss structurally impossible rather than merely unlikely, since
	 * `uart_poll_out` then waits for the host instead of writing into a full
	 * buffer.
	 *
	 * The DK already assigns the pins: `uart20_default` carries UART_RTS on
	 * P1.06 and UART_CTS on P1.07 alongside TX P1.04 / RX P1.05, routed
	 * through the onboard J-Link OB to VCOM1. Nothing here rewires
	 * anything -- it only asks the UARTE to honour lines the board file
	 * already declared. */
	hw-flow-control;
};
```

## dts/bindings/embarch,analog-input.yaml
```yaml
# One analog input of the dev bench's analog source (an analog sensor, e.g. a
# microphone breakout, wired to a dev-kit pin). The analog-source code reads
# the SAADC input number from here; no pin is hard-coded in C.
description: EmbArch dev-bench analog input

compatible: "embarch,analog-input"

include: base.yaml

properties:
  label:
    required: true
    description: |
      Name of the input as the study and the sample-stream start header show
      it, e.g. "A0" for the Arduino-header pin.

  saadc-input:
    type: int
    required: true
    description: |
      SAADC analog input number, N for AINn (nrf_saadc_input_t NRF_SAADC_AINn).
      Must be the SAADC input of the pin in `gpios`.

  gpios:
    type: phandle-array
    required: true
    description: |
      The pin carrying the input. Documents the wiring only; the pin is
      never configured as a digital GPIO, the SAADC takes it over.
```

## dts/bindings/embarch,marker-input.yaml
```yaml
# A digital input the operator presses to drop a marker into the analog
# sample stream (a dev-kit button).
description: EmbArch dev-bench marker input

compatible: "embarch,marker-input"

include: base.yaml

properties:
  gpios:
    type: phandle-array
    required: true
    description: |
      The marker pin, with its polarity and pull flags
      (e.g. GPIO_PULL_UP | GPIO_ACTIVE_LOW for a button to ground).
```

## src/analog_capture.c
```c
/*
 * One analog capture session on the dev bench (dev-bench decisions 60, 64):
 * the study's analog tap starts it at the tap's rate and the tap's close ends
 * it; there is no other control command. The marker input is the board's
 * `embarch,marker-input` chosen node; a board without one captures without
 * marker edges.
 */

#include <errno.h>

#include <zephyr/devicetree.h>
#include <zephyr/drivers/gpio.h>
#include <zephyr/kernel.h>
#include <zephyr/logging/log.h>

#include "analog_capture.h"
#include "analog_stream.h"
#include "samples_port.h"

LOG_MODULE_REGISTER(analog_capture, LOG_LEVEL_INF);

#define MARKER_NODE DT_CHOSEN(embarch_marker_input)

#if DT_HAS_CHOSEN(embarch_marker_input)
static const struct gpio_dt_spec m_marker = GPIO_DT_SPEC_GET(MARKER_NODE, gpios);
static struct gpio_callback m_marker_cb;

static void marker_isr(const struct device *dev, struct gpio_callback *cb, uint32_t pins)
{
	ARG_UNUSED(cb);
	ARG_UNUSED(pins);

	/* Logical level: 1 while the marker is asserted (a pressed button on an
	 * active-low pin). */
	analog_stream_marker_edge(gpio_pin_get_dt(&m_marker) > 0, k_cycle_get_32());
}

static int marker_enable(void)
{
	int err;

	if (!gpio_is_ready_dt(&m_marker)) {
		LOG_ERR("%s: the marker GPIO is not ready", __func__);
		return -ENODEV;
	}
	err = gpio_pin_configure_dt(&m_marker, GPIO_INPUT);
	if (err != 0) {
		LOG_ERR("%s: configuring the marker failed (%d)", __func__, err);
		return err;
	}
	gpio_init_callback(&m_marker_cb, marker_isr, BIT(m_marker.pin));
	err = gpio_add_callback(m_marker.port, &m_marker_cb);
	if (err != 0) {
		LOG_ERR("%s: adding the marker callback failed (%d)", __func__, err);
		return err;
	}
	err = gpio_pin_interrupt_configure_dt(&m_marker, GPIO_INT_EDGE_BOTH);
	if (err != 0) {
		LOG_ERR("%s: enabling the marker interrupt failed (%d)", __func__, err);
		(void)gpio_remove_callback(m_marker.port, &m_marker_cb);
	}
	return err;
}

static void marker_disable(void)
{
	(void)gpio_pin_interrupt_configure_dt(&m_marker, GPIO_INT_DISABLE);
	(void)gpio_remove_callback(m_marker.port, &m_marker_cb);
}
#else
static int marker_enable(void)
{
	return 0;
}

static void marker_disable(void)
{
}
#endif

int analog_capture_start(uint32_t sample_hz, uint8_t channel)
{
	struct analog_stream_config config = {
		.backend = &analog_source_backend,
		.sink = {.write = samples_port_write},
		.params = {.sample_rate_hz = sample_hz, .channel = channel, .channel_count = 1U},
		.cycles_per_sec = sys_clock_hw_cycles_per_sec(),
		.board = CONFIG_BOARD,
		.image_version = APP_FIRMWARE_VERSION,
	};
	int err = samples_port_reset();

	if (err != 0) {
		LOG_ERR("%s: no samples port (%d)", __func__, err);
		return err;
	}
	err = marker_enable();
	if (err != 0) {
		return err;
	}
	err = analog_stream_start(&config);
	if (err != 0) {
		marker_disable();
	}
	return err;
}

uint32_t analog_capture_stop(void)
{
	struct analog_stream_stats stats;
	bool was_running = analog_stream_running();

	analog_stream_stop(&stats);
	if (!was_running) {
		/* analog_stream keeps the last session's totals until the next
		 * start. A tap whose capture never started (or that a stop already
		 * ended) has lost nothing of its own, and the totals left over
		 * would be reported as its `StreamClose.dropped`. */
		return 0;
	}
	marker_disable();
	return stats.blocks_lost;
}
```

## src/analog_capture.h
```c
/* The dev bench's analog capture session: the glue between a study's analog
 * tap, the board's analog source backend, the marker input and the samples
 * port. */
#ifndef EMBARCH_ANALOG_CAPTURE_H_
#define EMBARCH_ANALOG_CAPTURE_H_

#include <stdint.h>

/* Starts a session at `sample_hz` on the study's `channel` index: backend
 * prepared, start header written to the samples port, sampling begun.
 * Returns 0 or a negative errno (-ENOTSUP where the board has no backend or
 * no samples port, -EINVAL for a rate or channel the board cannot do). */
int analog_capture_start(uint32_t sample_hz, uint8_t channel);

/* Ends the session and returns how many blocks it lost. Safe with no session. */
uint32_t analog_capture_stop(void);

#endif /* EMBARCH_ANALOG_CAPTURE_H_ */
```

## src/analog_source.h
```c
/*
 * The analog source: what the dev bench samples and how the samples reach
 * analog_stream.c. SoC-neutral, with one backend per SoC family; the only one
 * today is analog_source_nrf52.c, a stated, narrow exception to the
 * portable-APIs-only rule (dev-bench decision 60).
 *
 * N-channel-ready: the channel count is a parameter and a delivery is
 * `ANALOG_SAMPLES_PER_BLOCK` frames of `channel_count` interleaved codes. The
 * v1 backend samples one channel.
 */
#ifndef EMBARCH_ANALOG_SOURCE_H_
#define EMBARCH_ANALOG_SOURCE_H_

#include <stdint.h>

#include <zephyr/autoconf.h>

/* Frames per block, per channel. Fixed by the owner (EMB-469 decision 7). */
#define ANALOG_SAMPLES_PER_BLOCK 256U

/* The block's edge offset is one byte, so a block can hold at most 256 frames. */
_Static_assert(ANALOG_SAMPLES_PER_BLOCK <= 256U, "a block's marker edge offset is 8 bits");

/* Most channels a build carries; sizes every block buffer. */
#define ANALOG_MAX_CHANNELS CONFIG_EMBARCH_ANALOG_MAX_CHANNELS

/* The ADC reference, numbered as the start header carries it. */
enum analog_reference {
	ANALOG_REFERENCE_INTERNAL = 0,
	ANALOG_REFERENCE_VDD_DIV4 = 1,
};

/* What a session asks of a backend. */
struct analog_source_params {
	/* The rate the study asked for; the backend reports the one it can
	 * reach in `analog_source_info.sample_rate_hz`. */
	uint32_t sample_rate_hz;
	/* The study's channel index into the board's analog inputs. */
	uint8_t channel;
	uint8_t channel_count;
};

/* What a prepared backend reports, and what the start header carries. */
struct analog_source_info {
	/* The rate the hardware will really run at. */
	uint32_t sample_rate_hz;
	uint8_t resolution_bits;
	uint8_t gain_numerator;
	uint8_t gain_denominator;
	enum analog_reference reference;
	uint8_t channel_count;
	/* VDD measured once while preparing. */
	uint16_t vdd_mv;
	/* The input's devicetree label, NUL-terminated. */
	const char *input_name;
};

/* Delivers one block's worth of frames: ANALOG_SAMPLES_PER_BLOCK frames of
 * `channel_count` interleaved raw codes, valid only for the call. `cycles` is
 * k_cycle_get_32() when the last frame was taken. May run in interrupt
 * context. */
typedef void (*analog_source_block_cb)(void *ctx, const int16_t *codes, uint32_t cycles);

struct analog_source_backend {
	/* Claims the hardware, calibrates it, measures VDD and configures the
	 * input, without sampling yet. Returns 0 or a negative errno. */
	int (*prepare)(const struct analog_source_params *params, struct analog_source_info *info);
	/* Starts sampling after a successful prepare; `cb` then runs once per
	 * block. Returns 0 or a negative errno. */
	int (*start)(analog_source_block_cb cb, void *ctx);
	/* Stops sampling and releases the hardware. No callback runs once it
	 * has returned. Safe after a prepare that was never started. */
	void (*stop)(void);
};

/* The backend this build has: nRF52's SAADC, or one whose prepare returns
 * -ENOTSUP. */
extern const struct analog_source_backend analog_source_backend;

#endif /* EMBARCH_ANALOG_SOURCE_H_ */
```
